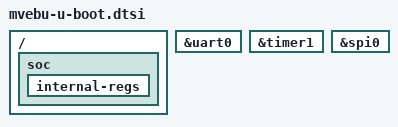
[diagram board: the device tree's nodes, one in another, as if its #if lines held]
#include <config.h>

#ifdef CONFIG_ARMADA_32BIT

/ {
	soc {
		u-boot,dm-all;
		internal-regs {
			u-boot,dm-all;
		};
	};
};

&uart0 {
	u-boot,dm-all;
};

#ifdef CONFIG_ARMADA_375
/* Armada 375 has multiple timers, use timer1 here */
&timer1 {
	u-boot,dm-all;
};
#else
&timer {
	u-boot,dm-all;
};
#endif

#ifdef CONFIG_SPL_SPI
&spi0 {
	u-boot,dm-all;
};
#endif

#endif
